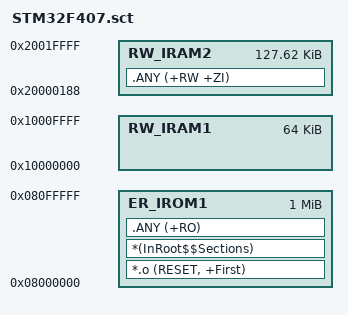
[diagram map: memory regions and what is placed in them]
; *************************************************************
; *** Scatter-Loading Description File generated by uVision ***
; *************************************************************

LR_IROM1 0x08000000 0x00100000  {    ; load region size_region
  ER_IROM1 0x08000000 0x00100000  {  ; load address = execution address
   *.o (RESET, +First)
   *(InRoot$$Sections)
   .ANY (+RO)
  }
  RW_IRAM1 0x10000000 0x00010000  {  ; CCM
  }
  RW_IRAM2 0x20000188 0x0001FE78 {
   .ANY (+RW +ZI)
  }
}

